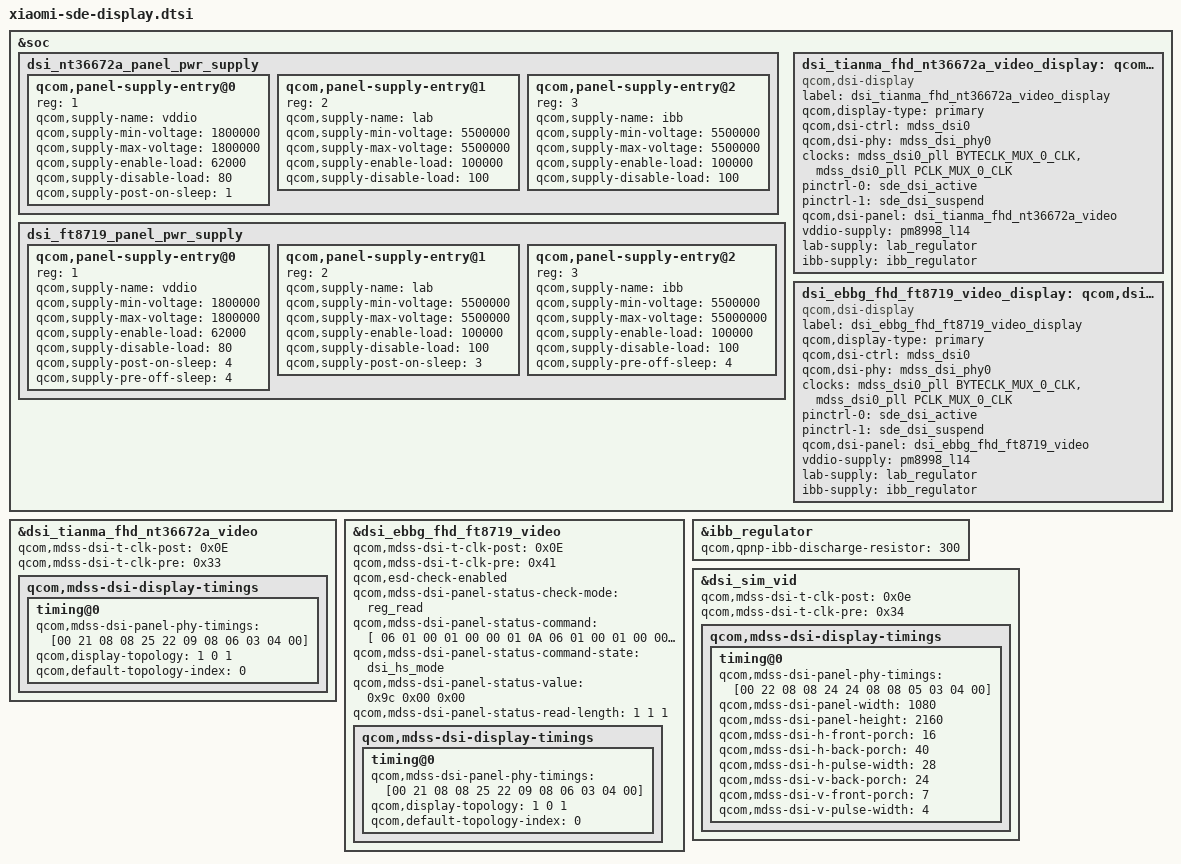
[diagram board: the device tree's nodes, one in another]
/* Copyright (c) 2016-2017, The Linux Foundation. All rights reserved.
 * Copyright (C) 2019 XiaoMi, Inc.
 *
 * This program is free software; you can redistribute it and/or modify
 * it under the terms of the GNU General Public License version 2 and
 * only version 2 as published by the Free Software Foundation.
 *
 * This program is distributed in the hope that it will be useful,
 * but WITHOUT ANY WARRANTY; without even the implied warranty of
 * MERCHANTABILITY or FITNESS FOR A PARTICULAR PURPOSE.  See the
 * GNU General Public License for more details.
 */

#include "beryllium/dsi-panel-tianma-fhd-nt36672a-video.dtsi"
#include "beryllium/dsi-panel-ebbg-fhd-ft8719-video.dtsi"

&soc {
	dsi_nt36672a_panel_pwr_supply: dsi_nt36672a_panel_pwr_supply {
		#address-cells = <1>;
		#size-cells = <0>;

		qcom,panel-supply-entry@0 {
			reg = <1>;
			qcom,supply-name = "vddio";
			qcom,supply-min-voltage = <1800000>;
			qcom,supply-max-voltage = <1800000>;
			qcom,supply-enable-load = <62000>;
			qcom,supply-disable-load = <80>;
			qcom,supply-post-on-sleep = <1>;
		};

		qcom,panel-supply-entry@1 {
			reg = <2>;
			qcom,supply-name = "lab";
			qcom,supply-min-voltage = <5500000>;
			qcom,supply-max-voltage = <5500000>;
			qcom,supply-enable-load = <100000>;
			qcom,supply-disable-load = <100>;
		};

		qcom,panel-supply-entry@2 {
			reg = <3>;
			qcom,supply-name = "ibb";
			qcom,supply-min-voltage = <5500000>;
			qcom,supply-max-voltage = <5500000>;
			qcom,supply-enable-load = <100000>;
			qcom,supply-disable-load = <100>;
		};
	};

	dsi_ft8719_panel_pwr_supply: dsi_ft8719_panel_pwr_supply {
		#address-cells = <1>;
		#size-cells = <0>;

		qcom,panel-supply-entry@0 {
			reg = <1>;
			qcom,supply-name = "vddio";
			qcom,supply-min-voltage = <1800000>;
			qcom,supply-max-voltage = <1800000>;
			qcom,supply-enable-load = <62000>;
			qcom,supply-disable-load = <80>;
			qcom,supply-post-on-sleep = <4>;
			qcom,supply-pre-off-sleep = <4>;
		};

		qcom,panel-supply-entry@1 {
			reg = <2>;
			qcom,supply-name = "lab";
			qcom,supply-min-voltage = <5500000>;
			qcom,supply-max-voltage = <5500000>;
			qcom,supply-enable-load = <100000>;
			qcom,supply-disable-load = <100>;
			qcom,supply-post-on-sleep = <3>;
		};

		qcom,panel-supply-entry@2 {
			reg = <3>;
			qcom,supply-name = "ibb";
			qcom,supply-min-voltage = <5500000>;
			qcom,supply-max-voltage = <55000000>;
			qcom,supply-enable-load = <100000>;
			qcom,supply-disable-load = <100>;
			qcom,supply-pre-off-sleep = <4>;
		};
	};

	dsi_tianma_fhd_nt36672a_video_display: qcom,dsi-display@21 {
		compatible = "qcom,dsi-display";
		label = "dsi_tianma_fhd_nt36672a_video_display";
		qcom,display-type = "primary";

		qcom,dsi-ctrl = <&mdss_dsi0>;
		qcom,dsi-phy = <&mdss_dsi_phy0>;
		clocks = <&mdss_dsi0_pll BYTECLK_MUX_0_CLK>,
			<&mdss_dsi0_pll PCLK_MUX_0_CLK>;
		clock-names = "mux_byte_clk", "mux_pixel_clk";

		pinctrl-names = "panel_active", "panel_suspend";
		pinctrl-0 = <&sde_dsi_active>;
		pinctrl-1 = <&sde_dsi_suspend>;

		qcom,dsi-panel = <&dsi_tianma_fhd_nt36672a_video>;
		vddio-supply = <&pm8998_l14>;
		lab-supply = <&lab_regulator>;
		ibb-supply = <&ibb_regulator>;
	};

	dsi_ebbg_fhd_ft8719_video_display: qcom,dsi-display@23 {
		compatible = "qcom,dsi-display";
		label = "dsi_ebbg_fhd_ft8719_video_display";
		qcom,display-type = "primary";

		qcom,dsi-ctrl = <&mdss_dsi0>;
		qcom,dsi-phy = <&mdss_dsi_phy0>;
		clocks = <&mdss_dsi0_pll BYTECLK_MUX_0_CLK>,
			<&mdss_dsi0_pll PCLK_MUX_0_CLK>;
		clock-names = "mux_byte_clk", "mux_pixel_clk";

		pinctrl-names = "panel_active", "panel_suspend";
		pinctrl-0 = <&sde_dsi_active>;
		pinctrl-1 = <&sde_dsi_suspend>;

		qcom,dsi-panel = <&dsi_ebbg_fhd_ft8719_video>;
		vddio-supply = <&pm8998_l14>;
		lab-supply = <&lab_regulator>;
		ibb-supply = <&ibb_regulator>;
	};
};

&dsi_tianma_fhd_nt36672a_video {
	qcom,mdss-dsi-t-clk-post = <0x0E>;
	qcom,mdss-dsi-t-clk-pre = <0x33>;
	qcom,mdss-dsi-display-timings {
		timing@0{
			qcom,mdss-dsi-panel-phy-timings = [00 21 08 08 25 22 09 08 06 03 04 00];
			qcom,display-topology = <1 0 1>;
			qcom,default-topology-index = <0>;
		};
	};
};

&dsi_ebbg_fhd_ft8719_video {
	qcom,mdss-dsi-t-clk-post = <0x0E>;
	qcom,mdss-dsi-t-clk-pre = <0x41>;

	qcom,esd-check-enabled;
	qcom,mdss-dsi-panel-status-check-mode = "reg_read";
	qcom,mdss-dsi-panel-status-command = [
						06 01 00 01 00 00 01 0A
						06 01 00 01 00 00 01 0B
						06 01 00 01 00 00 01 0D
						];
	qcom,mdss-dsi-panel-status-command-state = "dsi_hs_mode";
	qcom,mdss-dsi-panel-status-value = <0x9c 0x00 0x00>;
	qcom,mdss-dsi-panel-status-read-length = <1 1 1>;

	qcom,mdss-dsi-display-timings {
		timing@0{
			qcom,mdss-dsi-panel-phy-timings = [00 21 08 08 25 22 09 08 06 03 04 00];
			qcom,display-topology = <1 0 1>;
			qcom,default-topology-index = <0>;
		};
	};
};

&ibb_regulator {
	qcom,qpnp-ibb-discharge-resistor = <300>;
};

&dsi_sim_vid {
	qcom,mdss-dsi-t-clk-post = <0x0e>;
	qcom,mdss-dsi-t-clk-pre = <0x34>;
	qcom,mdss-dsi-display-timings {
		timing@0{
			qcom,mdss-dsi-panel-phy-timings = [00 22 08 08 24 24 08
				08 05 03 04 00];
			qcom,mdss-dsi-panel-width = <1080>;
			qcom,mdss-dsi-panel-height = <2160>;
			qcom,mdss-dsi-h-front-porch = <16>;
			qcom,mdss-dsi-h-back-porch = <40>;
			qcom,mdss-dsi-h-pulse-width = <28>;
			qcom,mdss-dsi-v-back-porch = <24>;
			qcom,mdss-dsi-v-front-porch = <7>;
			qcom,mdss-dsi-v-pulse-width = <4>;
		};
	};
};
